VERSION ""

NS_ :

BS_:

BU_: BLE GEO IO MASTER MOTOR SENSOR

BO_ 10 BLE_COMM_CMD: 1 BLE
 SG_ BLE_COMM_CMD_enum : 0|8@1+ (1,0) [0|0] "" MASTER

BO_ 100 MASTER_SYSTEM_CMD: 1 MASTER
 SG_ MASTER_SYSTEM_CMD_enum : 0|8@1+ (1,0) [0|0] "" BLE,GEO,IO,MOTOR,SENSOR

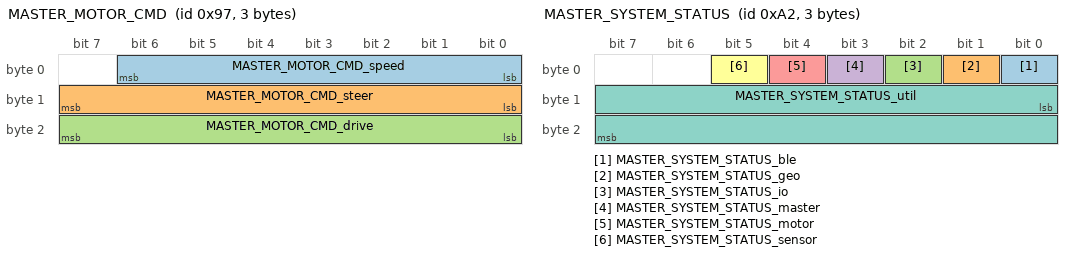
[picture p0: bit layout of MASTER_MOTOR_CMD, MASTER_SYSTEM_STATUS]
BO_ 151 MASTER_MOTOR_CMD: 3 MASTER
 SG_ MASTER_MOTOR_CMD_speed : 0|7@1+ (1,0) [0|100] "%" MOTOR,IO
 SG_ MASTER_MOTOR_CMD_steer : 8|8@1+ (1,0) [0|0] "" MOTOR,IO
 SG_ MASTER_MOTOR_CMD_drive : 16|8@1+ (1,0) [0|0] "" MOTOR,IO

BO_ 162 MASTER_SYSTEM_STATUS: 3 MASTER
 SG_ MASTER_SYSTEM_STATUS_ble : 0|1@1+ (1,0) [0|0] "" IO,BLE
 SG_ MASTER_SYSTEM_STATUS_geo : 1|1@1+ (1,0) [0|0] "" IO,BLE
 SG_ MASTER_SYSTEM_STATUS_io : 2|1@1+ (1,0) [0|0] "" IO,BLE
 SG_ MASTER_SYSTEM_STATUS_master : 3|1@1+ (1,0) [0|0] "" IO,BLE
 SG_ MASTER_SYSTEM_STATUS_motor : 4|1@1+ (1,0) [0|0] "" IO,BLE
 SG_ MASTER_SYSTEM_STATUS_sensor : 5|1@1+ (1,0) [0|0] "" IO,BLE
 SG_ MASTER_SYSTEM_STATUS_util : 8|16@1+ (0.01,0) [0|100] "%" IO,BLE

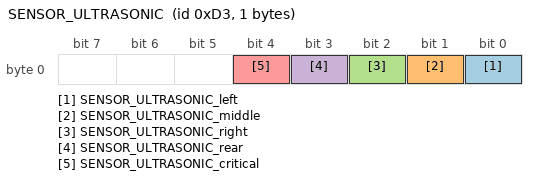
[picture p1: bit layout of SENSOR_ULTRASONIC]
BO_ 211 SENSOR_ULTRASONIC: 1 SENSOR
 SG_ SENSOR_ULTRASONIC_left : 0|1@1+ (1,0) [0|0] "" MASTER,IO
 SG_ SENSOR_ULTRASONIC_middle : 1|1@1+ (1,0) [0|0] "" MASTER,IO
 SG_ SENSOR_ULTRASONIC_right : 2|1@1+ (1,0) [0|0] "" MASTER,IO
 SG_ SENSOR_ULTRASONIC_rear : 3|1@1+ (1,0) [0|0] "" MASTER,IO
 SG_ SENSOR_ULTRASONIC_critical : 4|1@1+ (1,0) [0|0] "" MASTER,IO

BO_ 213 SENSOR_BATT: 1 SENSOR
 SG_ SENSOR_BATT_stat : 0|7@1+ (1,0) [0|100] "%" MASTER,IO

BO_ 214 SENSOR_HEARTBEAT: 4 SENSOR
 SG_ SENSOR_HEARTBEAT_rx_bytes : 0|16@1+ (1,0) [0|0] "bytes" MASTER
 SG_ SENSOR_HEARTBEAT_tx_bytes : 16|16@1+ (1,0) [0|0] "bytes" MASTER

BO_ 311 BLE_CHCK_PT: 8 BLE
 SG_ BLE_CHCK_PT_lat : 0|32@1+ (0.000001,0) [0|0] "degrees" GEO
 SG_ BLE_CHCK_PT_long : 32|32@1+ (0.000001,0) [0|0] "degrees" GEO

BO_ 314 BLE_HEARTBEAT: 4 BLE
 SG_ BLE_HEARTBEAT_rx_bytes : 0|16@1+ (1,0) [0|0] "bytes" MASTER
 SG_ BLE_HEARTBEAT_tx_bytes : 16|16@1+ (1,0) [0|0] "bytes" MASTER

BO_ 361 BLE_MAP_START_DATA: 8 BLE
 SG_ BLE_MAP_START_DATA_lat : 0|32@1+ (0.000001,0) [0|0] "degrees" IO
 SG_ BLE_MAP_START_DATA_long : 32|32@1+ (0.000001,0) [0|0] "degrees" IO

BO_ 362 BLE_MAP_DEST_DATA: 8 BLE
 SG_ BLE_MAP_DEST_DATA_lat : 0|32@1+ (0.000001,0) [0|0] "degrees" IO
 SG_ BLE_MAP_DEST_DATA_long : 32|32@1+ (0.000001,0) [0|0] "degrees" IO

BO_ 411 GEO_DIRECTION: 1 GEO
 SG_ GEO_DIRECTION_enum : 0|8@1+ (1,0) [0|0] "" MASTER

BO_ 413 GEO_DEST_RCHD: 1 GEO
 SG_ GEO_DEST_RCHD_stat : 0|1@1+ (1,0) [0|1] "" MASTER,IO

BO_ 414 GEO_HEARTBEAT: 4 GEO
 SG_ GEO_HEARTBEAT_rx_bytes : 0|16@1+ (1,0) [0|0] "bytes" MASTER
 SG_ GEO_HEARTBEAT_tx_bytes : 16|16@1+ (1,0) [0|0] "bytes" MASTER

BO_ 421 GEO_LOCATION: 8 GEO
 SG_ GEO_LOCATION_lat : 0|32@1+ (0.000001,0) [0|0] "degrees" IO,BLE
 SG_ GEO_LOCATION_long : 32|32@1+ (0.000001,0) [0|0] "degrees" IO,BLE

BO_ 461 GEO_COMPASS: 2 GEO
 SG_ GEO_COMPASS_mag : 0|9@1+ (1,0) [0|0] "" IO

BO_ 514 MOTOR_HEARTBEAT: 4 MOTOR
 SG_ MOTOR_HEARTBEAT_rx_bytes : 0|16@1+ (1,0) [0|0] "bytes" MASTER
 SG_ MOTOR_HEARTBEAT_tx_bytes : 16|16@1+ (1,0) [0|0] "bytes" MASTER

BO_ 561 MOTOR_SPEED: 2 MOTOR
 SG_ MOTOR_SPEED_actual : 0|14@1+ (0.01,0) [0|100.00] "rpm" IO

BO_ 614 IO_HEARTBEAT: 4 IO
 SG_ IO_HEARTBEAT_rx_bytes : 0|16@1+ (1,0) [0|0] "bytes" MASTER
 SG_ IO_HEARTBEAT_tx_bytes : 16|16@1+ (1,0) [0|0] bytes"" MASTER

CM_ BU_ BLE "The communication bridge module of the car";
CM_ BU_ GEO "The geocontroller module of the car";
CM_ BU_ IO "The input output controller of the car";
CM_ BU_ MASTER "The master controller of the car";
CM_ BU_ MOTOR "The motor controller of the car";
CM_ BU_ SENSOR "The sensor controller of the car";
CM_ BO_ 010 "The wake-up message for the master controller";
CM_ BO_ 100 "The system commands for all the modules";

BA_DEF_ "BusType" STRING ;
BA_DEF_ BO_ "GenMsgCycleTime" INT 0 0;
BA_DEF_ SG_ "FieldType" STRING ;

BA_DEF_DEF_ "BusType" "CAN";
BA_DEF_DEF_ "FieldType" "";
BA_DEF_DEF_ "GenMsgCycleTime" 0;

BA_ "GenMsgCycleTime" BO_ 134 1000;
BA_ "GenMsgCycleTime" BO_ 214 1000;
BA_ "GenMsgCycleTime" BO_ 314 1000;
BA_ "GenMsgCycleTime" BO_ 414 1000;
BA_ "GenMsgCycleTime" BO_ 514 1000;
BA_ "GenMsgCycleTime" BO_ 614 1000;

BA_ "FieldType" SG_ 10 BLE_COMM_CMD_enum "BLE_COMM_CMD";
BA_ "FieldType" SG_ 100 MASTER_SYSTEM_CMD_enum "MASTER_SYSTEM_CMD";
BA_ "FieldType" SG_ 151 MASTER_MOTOR_CMD_steer "MOTOR_STEER";
BA_ "FieldType" SG_ 151 MASTER_MOTOR_CMD_drive "MOTOR_DRIVE";
BA_ "FieldType" SG_ 411 GEO_DIRECTION_enum "NAVIGATION_DIR";

VAL_ 10 BLE_COMM_CMD_enum 0 "COMM_STOP" 1 "COMM_START" 2 "COMM_RESET" ;
VAL_ 100 MASTER_SYSTEM_CMD_enum 0 "SYSTEM_STOP" 1 "SYSTEM_START" 2 "SYSTEM_RESET" ;
VAL_ 151 MASTER_MOTOR_CMD_steer 0 "STEER_LEFT" 1 "STEER_HALF_LEFT" 2 "STEER_RIGHT" 3 "STEER_HALF_RIGHT" 4 "STEER_FORWARD" 5 "STEER_REVERSE";
VAL_ 151 MASTER_MOTOR_CMD_drive 0 "STOP" 1 "START" 2 "BRAKE" 3 "RESUME";
VAL_ 411 GEO_DIRECTION_enum 0 "DIR_LEFT" 1 "DIR_HALF_LEFT" 2 "DIR_RIGHT" 3 "DIR_HALF_RIGHT" 4 "DIR_FORWARD" 5 "DIR_REVERSE";
